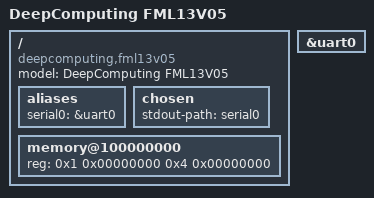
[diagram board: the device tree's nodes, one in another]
// SPDX-License-Identifier: (GPL-2.0 OR MIT)
/*
 * Copyright (C) 2024 DeepComputing (HK) Limited
 */

#include "k3.dtsi"

/ {
	model = "DeepComputing FML13V05";
	compatible = "deepcomputing,fml13v05", "spacemit,k3";

	aliases {
		serial0 = &uart0;
	};

	chosen {
		stdout-path = "serial0";
	};

	memory@100000000 {
		device_type = "memory";
		reg = <0x1 0x00000000 0x4 0x00000000>;
	};
};

&uart0 {
	status = "okay";
};
